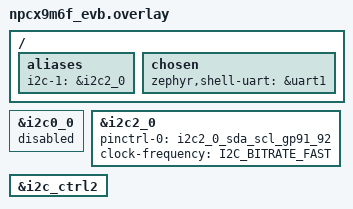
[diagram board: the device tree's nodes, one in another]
/ {
	aliases {
		/* For i2c test suites */
		i2c-1 = &i2c2_0;
	};

	chosen {
		zephyr,shell-uart = &uart1;
	};
};

&i2c0_0 {
	status = "disabled";
};

&i2c2_0 {
	status = "okay";
	pinctrl-0 = <&i2c2_0_sda_scl_gp91_92>;
	pinctrl-names = "default";
	clock-frequency = <I2C_BITRATE_FAST>;
};

&i2c_ctrl2 {
	status = "okay";
};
